# NANO103AE_v1 register map
File version: 1.0
Registers are 32-bit, read-write, reset 0x0 unless marked. A register's access mark holds for its fields unless they carry their own. Offsets are from the block's base; [hi:lo] are bit positions; {n}, {i} and the like mark numbered series; 'fields as' and 'values as' point back to an identical list.

## ADC — ADC Register Map
Base 0x400E0000
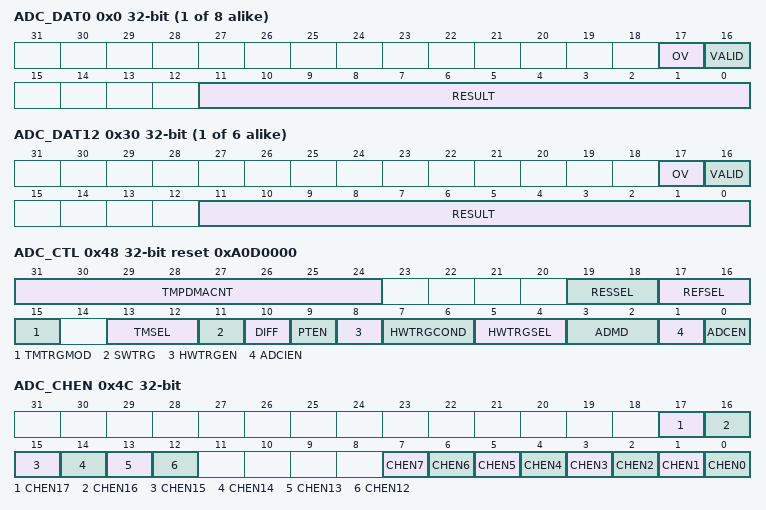
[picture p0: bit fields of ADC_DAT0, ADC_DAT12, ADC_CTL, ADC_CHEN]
{0x0+4i} ADC_DAT{i} ro (i=0..7) — A/D Data Register {i}
  [17] OV — Overrun Flag. If converted data in RESULT (ADC_DAT[11:0]) has not been read before the new conversion result is loaded to this register, OVis set to 1. It is cleared by hardware after the ADC_DATx register is read.
    0=Data in RESULT (ADC_DAT[11:0]) is recent conversion result; 1=Data in RESULT (ADC_DAT[11:0]) overwrote
  [16] VALID — Valid Flag. This bit is set to 1 when ADC conversion is completed and cleared by hardware after the ADC_DATx register is read.
    0=Data in RESULT (ADC_DAT[11:0]) bits is not valid; 1=Data in RESULT (ADC_DAT[11:0]) bits is valid
  [11:0] RESULT — A/D Conversion Result. This field contains conversion result of ADC.
{0x0+4i} ADC_DAT{i} ro (i=12..17) — A/D Data Register {i}
  fields as ADC_DAT0
0x48 ADC_CTL reset 0xA0D0000 — A/D Control Register
  [31:24] TMPDMACNT — Timer Event PDMA Count. When each timer event occur PDMA will transfer TMPDMACNT +1 ADC result in the amount of this register setting. Note: The total amount of PDMA transferring data should be set in PDMA byte count register. When PDMA finish is set, ADC will not be enabled and will start transfer even though the timer event occurred.
  [19:18] RESSEL — Resolution Selection
    0=6-bit. ADC result will put at RESULT(ADC_DATx[5:0]); 1=8-bit. ADC result will put at RESULT(ADC_DATx[7:0]); 2=10-bit. ADC result will put at RESULT(ADC_DATx[9:0]); 3=12-bit. ADC result will put at RESULT(ADC_DATx[11:0])
  [17:16] REFSEL — Reference Voltage Source Selection
    0=Select; 1=Select; 2=Select
  [15] TMTRGMOD — Timer Event Trigger ADC Conversion Mode. Note1: setting TMSEL (ADC_CTL[13:12]) to select timer event from timer0~3. Note2:If timer event is used as ADC trigger source, ADCEN (ADC_CTL[0]) needs to be disabled.
    0=Timer event trigger ADC conversion disabled; 1=ADC can be start to conversion by timer out event
  [13:12] TMSEL — Select A/D Enable Time-out Source. Selects one of four timer events sourceto trigger ADC starts to convert.
    {v}=TMR{v} (v=0..3)
  [11] SWTRG — Software Trigger A/D Conversion Start. ADC can be start to convert from three sources: software write, external pin STADC and PWM trigger. SWTRG(ADC_CTL[11]) is cleared to 0 by hardware automatically at the end of single mode and single-cycle scan mode on specified channels. In continuous scan mode, A/D conversion is continuously performed sequentially unless software writes 0 to this bit or chip reset. Note: After ADC conversion is done, SW needs to wait at least one ADC clock before to set this bit high again.
    0=Conversion stopped and A/D converter enter idle state; 1=Conversion starts
  [10] DIFF — Differential Mode Selection. Note: Calibration should calibrated each time when switching between single-ended and differential mode.
    0=ADC is operated in single-ended mode; 1=ADC is operated in differential mode
  [9] PTEN — PDMA Transfer EnableBit. When A/D conversion is completed, the converted data is loaded into ADC_DATx, software can enable this bit to generate a PDMA data transfer request.
    0=PDMA data transfer Disabled; 1=PDMA data transfer in ADC_DATx Enabled
  [8] HWTRGEN — Hardware External Trigger EnableBit. Enable or disable triggering of A/D conversion by external STADC pin. If external trigger is enabled, ADC starts to convert by the selected hardware trigger source.
    0=External trigger Disabled; 1=External trigger Enabled
  [7:6] HWTRGCOND — Hardware External Trigger Condition. These two bits decide external pin STADC trigger event is level or edge. The signal must be kept at stable state at least 8 PCLKs for level trigger and 4 PCLKs at high and low state.
    0=Low level; 1=High level; 2=Falling edge; 3=Rising edge
  [5:4] HWTRGSEL — Hardware Trigger Source Select Bit. In hardware trigger mode, ADC starts to convert by the external trigger from STADC pin or PWM trigger. Note:Software should disable HWTRGEN (ADC_CTL[8]) and clear SWTRG (ADC_CTL[11]) before change HWTRGSEL (ADC_CTL[5:4]).
    0=A/D conversion is started by external STADC pin; 3=A/D conversion is started by PWM0 trigger
  [3:2] ADMD — A/D Converter Operation Mode
    0=Single conversion; 2=Single-cycle scan; 3=Continuous scan
  [1] ADCIEN — A/D Interrupt EnableBit. A/D conversion end interrupt request is generated if ADCIEN(ADC_CTL[1]) bit is set to 1.
    0=A/D interrupt function Disabled; 1=A/D interrupt function Enabled
  [0] ADCEN — A/D Converter EnableBit. Note: Before starting A/D conversion function, this bit should be set to 1. Clear it to 0 to disable A/D converter analog circuit to save power consumption.
    0=A/D Converter Disabled; 1=A/D Converter Enabled
0x4C ADC_CHEN — A/D Channel Enable Register
  [17] CHEN17 — Analog Input Channel 17 EnableBit (ConvertAVSS)
    0=Channel 17 Disabled; 1=Channel 17 Enabled
  [16] CHEN16 — Analog Input Channel 16 EnableBit (Convert AVDD)
    0=Channel 16 Disabled; 1=Channel 16 Enabled
  [15] CHEN15 — Analog Input Channel 15 EnableBit (Convert Int_VREF)
    0=Channel 15 Disabled; 1=Channel 15 Enabled
  [14] CHEN14 — Analog Input Channel 14 EnableBit (Convert VTEMP)
    0=Channel 14 Disabled; 1=Channel 14 Enabled
  [13] CHEN13 — Analog Input Channel 13 Enable Bit (Convert VBAT)
    0=Channel 13 Disabled; 1=Channel 13 Enabled
  [12] CHEN12 — Analog Input Channel 12 Enable Bit (Convert VBG)
    0=Channel 12 Disabled; 1=Channel 12 Enabled
  [7] CHEN7 — Analog Input Channel 7 EnableBit (Convert Input Voltage From PA.7)
    0=Channel 7 Disabled; 1=Channel 7 Enabled
  [6] CHEN6 — Analog Input Channel 6 EnableBit (Convert Input Voltage From PA.6)
    0=Channel 6 Disabled; 1=Channel 6 Enabled
  [5] CHEN5 — Analog Input Channel 5 EnableBit (Convert Input Voltage From PA.5)
    0=Channel 5 Disabled; 1=Channel 5 Enabled
  [4] CHEN4 — Analog Input Channel 4 EnableBit (Convert Input Voltage From PA.4)
    0=Channel 4 Disabled; 1=Channel 4 Enabled
  [3] CHEN3 — Analog Input Channel 3 EnableBit (Convert Input Voltage From PA.3)
    0=Channel 3 Disabled; 1=Channel 3 Enabled
  [2] CHEN2 — Analog Input Channel 2 EnableBit (Convert Input Voltage From PA.2)
    0=Channel 2 Disabled; 1=Channel 2 Enabled
  [1] CHEN1 — Analog Input Channel 1 EnableBit (Convert Input Voltage From PA.1)
    0=Channel 1 Disabled; 1=Channel 1 Enabled
  [0] CHEN0 — Analog Input Channel 0 Enable Bit (Convert Input Voltage From PA.0). Note:If software enables more than one channel, the channel with the smallest number will be selected and the other enabled channels will be ignored.
    0=Channel 0 Disabled; 1=Channel 0 Enabled
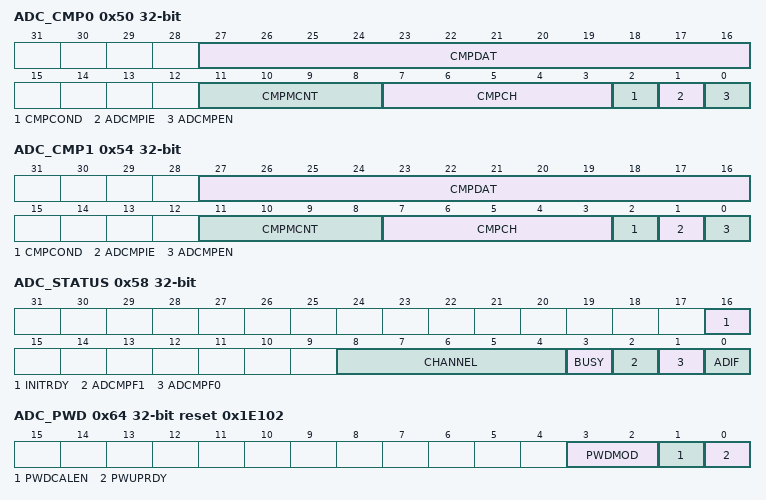
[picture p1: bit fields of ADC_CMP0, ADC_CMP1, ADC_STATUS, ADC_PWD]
0x50 ADC_CMP0 — A/D Compare Register 0
  [27:16] CMPDAT — Comparison Data. The 12 bits data is used to compare with conversion result of specified channel. Software can use it to monitor the external analog input pin voltage variation in scan mode without imposing a load on software.
  [11:8] CMPMCNT — Compare Match Count. When the specified A/D channel analog conversion result matches the compare condition defined by CMPCOND (ADC_CMPx[2]), the internal match counter will increase 1. Note:When the internal counter reaches the value to (CMPMCNT+1), the ADCMPFx (ADC_STATUS[2:1]) bit will be set.
  [7:3] CMPCH — Compare Channel Selection. Set this field to select which channel's result to be compared. Note: Valid setting of this field is channel 0~17, but channel 8~12 are reserved.
  [2] CMPCOND — Compare Condition. Note: When the internal counter reaches the value to (CMPMATCNT +1), the ADCMPFx (ADC_STATUS[2:1]) bit will be set.
    0=Set the compare condition as that when a A/D conversion result is less than the CMPDAT(ADC_CMPx[27:16]), the internal match counter will increase one; 1=Set the compare condition as that when a A/D conversion result is more than or equal to the CMPDAT(ADC_CMPx[27:16]), the internal match counter will increase one
  [1] ADCMPIE — A/D Compare Interrupt EnableBit. If the compare function is enabled and the compare condition matches the setting of CMPCOND (ADC_CMPx[2]) and CMPMCNT (ADC_CMPx[11:8]), ADCMPFx(ADC_STATUS[2:1]) bit will be asserted, in the meanwhile, if ADCMPIE(ADC_CMPx[1]) is set to 1, a compare interrupt request will generate.
    0=Compare function interrupt Disabled; 1=Compare function interrupt Enabled
  [0] ADCMPEN — A/D Compare EnableBit. Set 1 to this bit to enable comparing CMPDAT (ADC_CMPx[27:16]) with specified channel conversion results when converted data is loaded into the ADC_DATx register. Note:When this bit is set to 1 and CMPMCNT (ADC_CMPx[11:8]) is 0, the ADCMPFx (ADC_STATUS[2:1]) will be set once the match is hit.
    0=Compare function Disabled; 1=Compare function Enabled
0x54 ADC_CMP1 — A/D Compare Register 1
  fields as ADC_CMP0
0x58 ADC_STATUS — A/D Status Register
  [16] INITRDY — ADC Initial Ready by Power-up Sequence Completed. Note: This bit will be set after system reset occurred and automatically cleared by power-up event.
    0=ADC not powered up after system reset; 1=ADC has been powered up since the last system reset
  [8:4] CHANNEL ro — Current Conversion Channel(Read Only)
  [3] BUSY ro — BUSY/IDLE(Read Only). Note:This bit is mirror of SWTRG (ADC_CTL [11]) bit.
    0=A/D converter is in idle state; 1=A/D converter is busy at conversion
  [2] ADCMPF1 — A/D Compare Flag1. When the selected channel A/D conversion result meets the setting condition in ADC_CMP1, this bit is set to 1. Note: This flag can be cleared by software writing 1 to it, when this flag is set, the matching counter will be reset to 0,and continue to count when user writes 1 to clear ADCMPF1 (ADC_STATUS[2]).
    0=Conversion result in ADC_DATx does not meet the CMPDAT (ADC_CMP1[27:16]) setting; 1=Conversion result in ADC_DATx meets the CMPDAT (ADC_CMP1[27:16]) setting
  [1] ADCMPF0 — A/D Compare Flag0. When the selected channel A/D conversion result meets the setting condition in ADC_CMP0, this bit is set to 1. This flag can be cleared by writing 1 to it. Note: This flag can be cleared by software writing 1 to it, when this flag is set, the matching counter will be reset to 0,and continue to count when user writes 1 to clear ADCMPF0 (ADC_STATUS[1]).
    0=Conversion result in ADC_DATx does not meet the CMPDAT (ADC_CMP0[27:16]) setting; 1=Conversion result in ADC_DATx meets the CMPDAT (ADC_CMP0[27:16]) setting
  [0] ADIF — A/D Conversion End Flag. A status flag that indicates the end of A/D conversion, ADIF (ADC_STATUS[0]) is set to 1 at these two conditions: When A/D conversion ends in single mode. When A/D conversion ends on all specified channels in scan mode. Note: This bit can be cleared to 0 by software writing 1.
0x60 ADC_PDMA ro — A/D PDMA Current Transfer Data Register
  [11:0] AD_PDMA — ADC PDMA Current Transfer Data(Read Only). During PDMAtransfer, reading these bits can monitor the current PDMA transfer data.
0x64 ADC_PWD reset 0x1E102 — A/D Power Management Register
  [3:2] PWDMOD — ADC Power Saving Mode. Set this bit fields to select ADC power saving mode. Note1: Different power saving mode has different power down/up sequence.To avoid ADC powering up with wrong sequence, user must keep PWMOD (ADC_PWD[3:2]) consistent each time in power down and power up. Note2:While the ADC is powered up from power saving mode (set to 00b/01b/11b) without calibration, the PWDCALEN(ADC_PWD[1]) is set to 0, and the calibration value will be reset.
    1=ADC Power-down mode; 2=ADC Standby mode
  [1] PWDCALEN — Power Up Calibration Function EnableBit. Note:This bit works together with CALSEL (ADC_CALCTL[3]),see the following {PWDCALEN,CALFBSEL}Description: PWDCALEN is 0 and CALFBSEL is 0: No need to calibrate. PWDCALEN is 0 and CALFBSEL is 1: No need to calibrate. PWDCALEN is 1 and CALFBSEL is 0: Load calibration word when power up. PWDCALEN is 1 and CALFBSEL is 1: Calibrate when power up.
    0=Power up without calibration; 1=Power up with calibration
  [0] PWUPRDY — ADC Power-up Sequence Completed and Ready for Conversion
    0=ADC is not ready for conversion, itmay be in power saving state or in the progress of power up; 1=ADC is ready for conversion
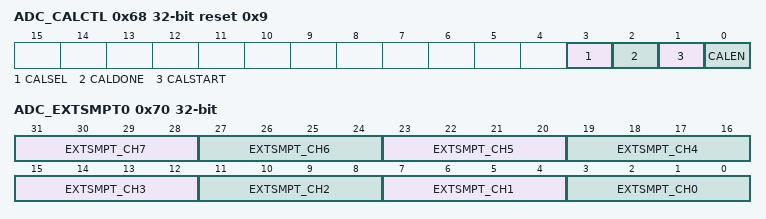
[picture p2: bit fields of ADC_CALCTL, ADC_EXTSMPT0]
0x68 ADC_CALCTL reset 0x9 — A/D Calibration Control Register
  [3] CALSEL — Calibration Functional Block Selection
    0=Load calibration functional block; 1=Calibration functional block
  [2] CALDONE — Calibrate Functional Block Done. Note:This bit is set by hardware and auto cleard by hardware, This bit can also be cleared by software writing 1.
    0=Not yet; 1=Selected calibrationfunctional block complete
  [1] CALSTART — Calibration Functional Block Start
    0=Stops calibration functional block; 1=Starts calibration functional block
  [0] CALEN — Calibration Function EnableBit. Enable this bit to turn on the calibration function block.
    0=Bypass calibrationfunctionalblock; 1=Enabledcalibrationfunctionalblock
0x6C ADC_CALWORD (reset mask 0xFFFFFF00) — A/D Calibration Load word Register
  [6:0] CALWORD — Calibration Word Bits. Write to this register with the previous calibration word before load calibration action, read this register after calibration done. Note:The calibration block contains two parts "CALIBRATION" and "LOAD CALIBRATION"; if thecalibration block configure as "CALIBRATION"; then this register represent the result of calibration when calibration is completed; if configure as "LOAD CALIBRATION" ; configure this register before loading calibration action, after loading calibration complete, the loaded calibration word will apply to the ADC;while in loading calibration function the loaded value will not be equal to the original CALWORD until calibration is done.
0x70 ADC_EXTSMPT0 — A/D Sampling Time Counter Register 0
  [4n+3:4n] EXTSMPT_CH{n} (n=1..7) — Additional ADC Sample Clockfor Channel {n}. The same as channel 0 description.
  [3:0] EXTSMPT_CH0 — Additional ADC Sample Clockfor Channel 0. If the ADC input is unstable, user can set this register to increase the sampling time to get a stable ADC input signal. The default sampling time is 1 ADC clocks. The additional clock number will be inserted to lengthen the sampling clock.
    0=Number of additional clock cycles is 0; 1=Number of additional clock cycles is 1; 2=Number of additional clock cycles is 2; 3=Number of additional clock cycles is 4; 4=Number of additional clock cycles is 8; 5=Number of additional clock cycles is 16; 6=Number of additional clock cycles is 32; 7=Number of additional clock cycles is 64; 8=Number of additional clock cycles is 128; 9=Number of additional clock cycles is 256; 10=Number of additional clock cycles is 512; {v}=Number of additional clock cycles is 1024 (v=11..15)
0x74 ADC_EXTSMPT1 — A/D Sampling Time Counter Register 1
  [19:16] EXTSMPT_INTCH — Additional ADC Sample Clock for Internal Channel (VTEMP, AVDD, AVSS, Int_VREF, VBAT, VBG). The same as channel 0 description.
